# GD32H77x register map
File version: 1.0
CPU: CM7 r1p2, little endian, MPU, FPU, 4 interrupt priority bits
Registers are 32-bit, read-write, reset 0x0 unless marked. A register's access mark holds for its fields unless they carry their own. Offsets are from the block's base; [hi:lo] are bit positions.

## RDCM — Resolver-to-digital module
Base 0x40016400
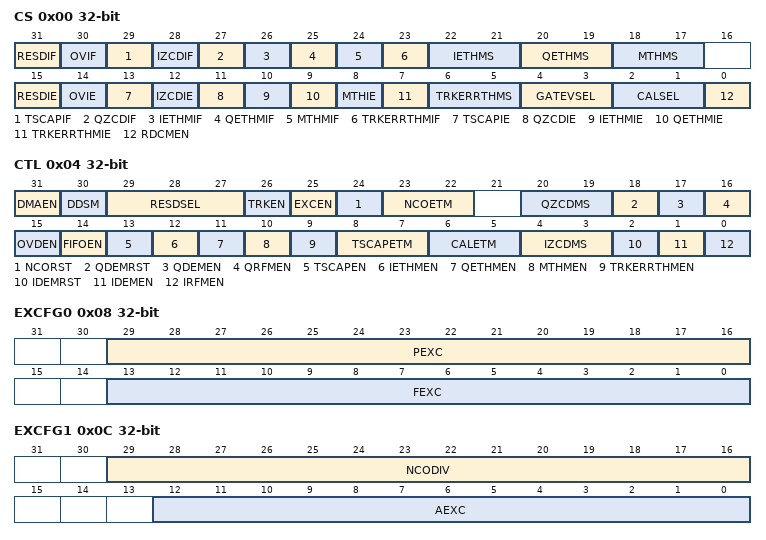
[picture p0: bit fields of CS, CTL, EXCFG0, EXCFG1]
0x00 CS — Control and status register
  [31] RESDIF — Result data interrupt flag.
  [30] OVIF — DMA transfer data register overflow interrupt flag
  [29] TSCAPIF — Timestamp counter capture interrupt flag.
  [28] IZCDIF — I channel zero crossing detection interrupt flag.
  [27] QZCDIF — Q channel zero crossing detection interrupt flag.
  [26] IETHMIF — I channel envelope signal threshold match interrupt flag.
  [25] QETHMIF — Q channel envelope signal threshold match interrupt flag.
  [24] MTHMIF — Monitor signal threshold match interrupt flag.
  [23] TRKERRTHMIF — Track error signal threshold match interrupt flag.
  [22:21] IETHMS — I channel envelope signal threshold mode selection
  [20:19] QETHMS — Q channel envelope signal threshold mode selection
  [18:17] MTHMS — Monitor signal mode selection
  [15] RESDIE — Interrupt enable for RESDIF
  [14] OVIE — Interrupt enable for OVIF
  [13] TSCAPIE — Interrupt enable for TSCAPIF
  [12] IZCDIE — Interrupt enable for IZCDIF
  [11] QZCDIE — Interrupt enable for QZCDIF
  [10] IETHMIE — Interrupt enable for IETHMIF
  [9] QETHMIE — Interrupt enable for QETHMIF
  [8] MTHIE — Interrupt enable for MTHMIF
  [7] TRKERRTHMIE — Interrupt enable for TRKERRTHMIF
  [6:5] TRKERRTHMS — Tracking error signal threshold mode selection.
  [4:3] GATEVSEL — Gate signal (timestamp trigger) valid selection
  [2:1] CALSEL — RDCM main chain calculation event selection.
  [0] RDCMEN — RDCM enable.
0x04 CTL access per field — Control register
  [31] DMAEN rw — DMA request enable
  [30] DDSM rw — DMA disable mode
  [29:27] RESDSEL rw — Result data register selection.
  [26] TRKEN rw — Track loop enable
  [25] EXCEN rw — Sinusoidal exciter enable
  [24] NCORST wo — Reset the phase of all NCOs (Exciter and I/Q reference frequency mixer) to the initial setting phase
  [23:22] NCOETM rw — External trigger mode for all NCOs (Excitor, I/Q Reference Frequency Mixer) calculation.
  [20:19] QZCDMS rw — Zero crossing detection mode selection in Q channel
  [18] QDEMRST wo — Q channel demodulator reset
  [17] QDEMEN rw — Q channel demodulator enable
  [16] QRFMEN rw — Q channel reference frequency mixer enable
  [15] OVDEN rw — DMA transfer overflow detection enable.
  [14] FIFOEN rw — Result data FIFO enable.
  [13] TSCAPEN rw — Timestamp counter capture enable.
  [12] IETHMEN rw — I channel envelope signal threshold match enable.
  [11] QETHMEN rw — Q channel envelope signal threshold match enable.
  [10] MTHMEN rw — Monitor signal threshold match enable.
  [9] TRKERRTHMEN rw — Track error signal threshold match enable.
  [8:7] TSCAPETM rw — External trigger mode for timestamp counter capture.
  [6:5] CALETM rw — External trigger mode for RDCM main chain calculation (high-pass filter, demodulator, tracking loop).
  [4:3] IZCDMS rw — Zero crossing detection mode selection in I channel
  [2] IDEMRST wo — I channel demodulator reset
  [1] IDEMEN rw — I channel demodulator enable
  [0] IRFMEN rw — I channel reference frequency mixer enable
0x08 EXCFG0 — Exciter configuration register 0
  [29:16] PEXC — Initial phase of the exciter
  [13:0] FEXC — Frequency of the exciter
0x0C EXCFG1 — Exciter configuration register 1
  [29:16] NCODIV — NCO(Excitror,I/Q reference frequency mixer) calculation frequency division factor
  [12:0] AEXC — Amplitude of the exciter
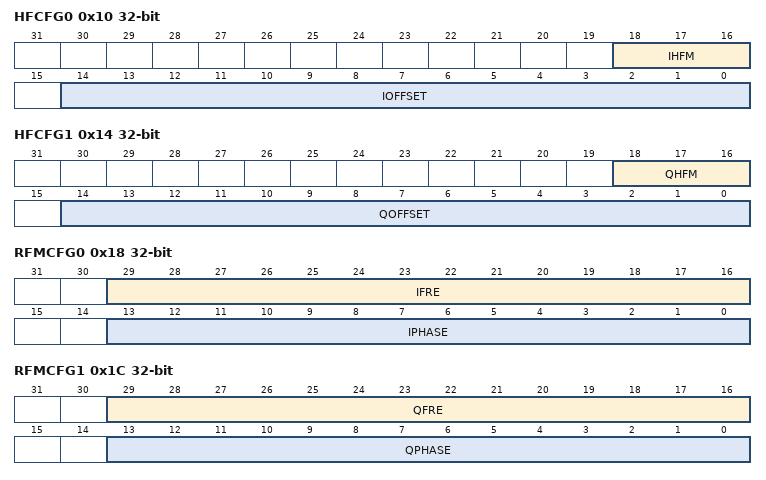
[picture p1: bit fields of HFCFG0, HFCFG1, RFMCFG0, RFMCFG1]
0x10 HFCFG0 — High pass filter configuration register 0
  [18:16] IHFM — I channel high-pass (offset compensation) filter mode
  [14:0] IOFFSET — I channel offset factor
0x14 HFCFG1 — High pass filter configuration register 1
  [18:16] QHFM — Q channel high-pass (offset compensation) filter mode
  [14:0] QOFFSET — Q channel offset factor
0x18 RFMCFG0 — Reference frequency mixer configuration register 0
  [29:16] IFRE — The frequency control word of the I channel reference frequency mixer.
  [13:0] IPHASE — Initial phase of the I channel reference frequency mixer.
0x1C RFMCFG1 — Reference frequency mixer configuration register 1
  [29:16] QFRE — The frequency control word of the Q channel reference frequency mixer.
  [13:0] QPHASE — Initial phase of the Q channel reference frequency mixer.
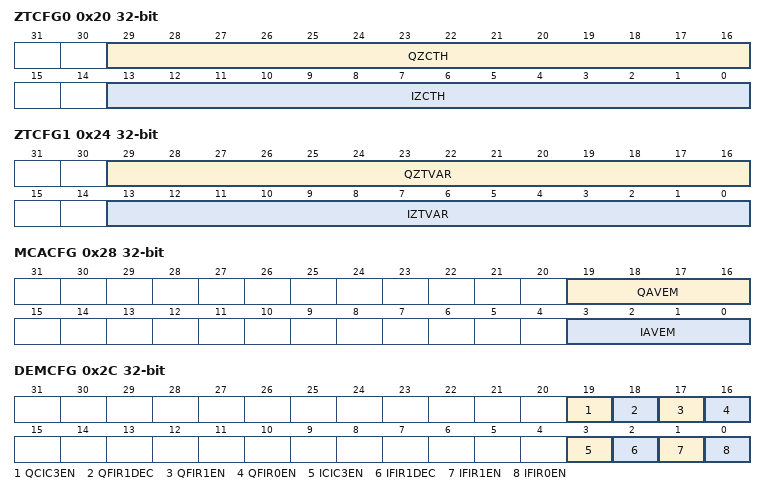
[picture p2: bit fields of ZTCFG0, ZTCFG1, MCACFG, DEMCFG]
0x20 ZTCFG0 — Zero crossing threshold configuration register 0
  [29:16] QZCTH — The threshold of mismatch counter value in zero crossing detection of Q channel.
  [13:0] IZCTH — The threshold of mismatch counter value in zero crossing detection of I channel.
0x24 ZTCFG1 — Zero crossing threshold configuration register 1
  [29:16] QZTVAR — The threshold variation range of mismatch counter value in zero crossing detection of Q channel.
  [13:0] IZTVAR — The threshold variation range of mismatch counter value in zero crossing detection of I channel.
0x28 MCACFG — Mismatch counter average configuration register
  [19:16] QAVEM — The mismatch counter average factor of Q channel.
  [3:0] IAVEM — The mismatch counter average factor of I channel.
0x2C DEMCFG — Demodulator configuration register
  [19] QCIC3EN — Q channel CIC3 filter enable
  [18] QFIR1DEC — Q channel FIR1 filter decimation rate
  [17] QFIR1EN — Q channel FIR1 filter enable
  [16] QFIR0EN — Q channel FIR0 filter enable
  [3] ICIC3EN — I channel CIC3 filter enable
  [2] IFIR1DEC — I channel FIR1 filter decimation rate
  [1] IFIR1EN — I channel FIR1 filter enable
  [0] IFIR0EN — I channel FIR0 filter enable
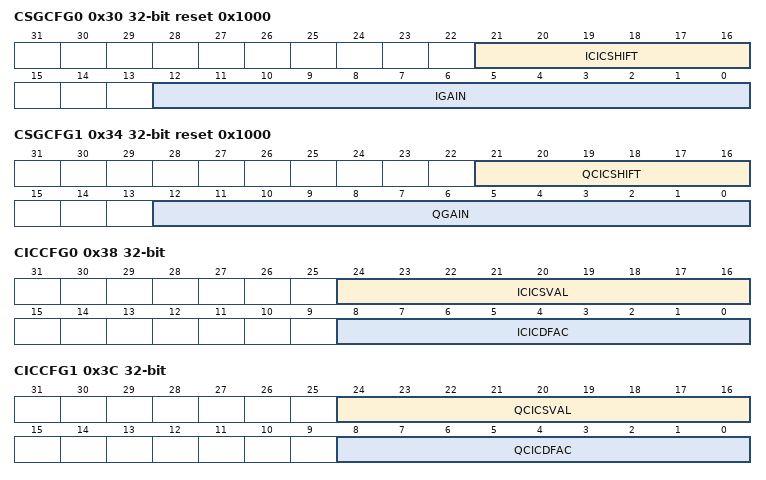
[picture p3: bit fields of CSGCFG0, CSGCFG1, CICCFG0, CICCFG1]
0x30 CSGCFG0 reset 0x1000 — CIC3 shift and gain configuration register 0
  [21:16] ICICSHIFT — I channel output shift
  [12:0] IGAIN — I channel gain factor
0x34 CSGCFG1 reset 0x1000 — CIC3 shift and gain configuration register 1
  [21:16] QCICSHIFT — Q channel output shift
  [12:0] QGAIN — Q channel gain factor
0x38 CICCFG0 — CIC3 configuration register 0
  [24:16] ICICSVAL — I channel CIC filter start value
  [8:0] ICICDFAC — I channel CIC filter decimation factor
0x3C CICCFG1 — CIC3 configuration register 1
  [24:16] QCICSVAL — Q channel CIC filter start value
  [8:0] QCICDFAC — Q channel CIC filter decimation factor
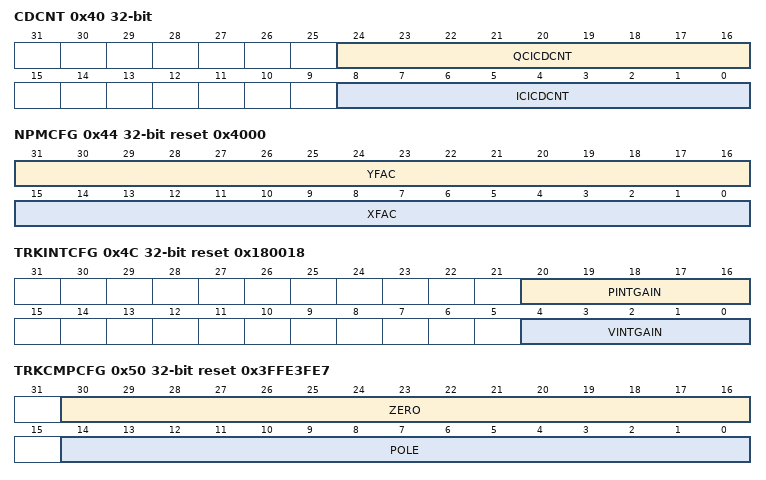
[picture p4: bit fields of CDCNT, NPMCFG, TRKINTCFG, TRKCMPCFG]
0x40 CDCNT ro — CIC3 decimation counter register
  [24:16] QCICDCNT — Q channel CIC3 filter decimation counter
  [8:0] ICICDCNT — I channel CIC3 Filter decimation counter
0x44 NPMCFG reset 0x4000 — Nonorthogonal phase mismatch configuration register
  [31:16] YFAC — Q channel nonorthogonal phase mismatch compensation factor Y.
  [15:0] XFAC — Q channel nonorthogonal phase mismatch compensation factor X.
0x48 TRKGAINCFG reset 0x1394FF16 — Tracking gain configuration register
  [28:0] TRKERRGAIN — The error acceleration gain factor.
0x4C TRKINTCFG reset 0x180018 — Tracking integrator configuration register
  [20:16] PINTGAIN — The position gain factor of integrator
  [4:0] VINTGAIN — The velocity gain factor of integrator
0x50 TRKCMPCFG reset 0x3FFE3FE7 — Tracking compensation configuration register
  [30:16] ZERO — The zero of compensation filter.
  [14:0] POLE — The pole of compensation filter.
0x54 VSFCFG — Velocity smooth filter configuration register
  [3:0] VSFM — The velocity smooth filter mode in tracking loop.
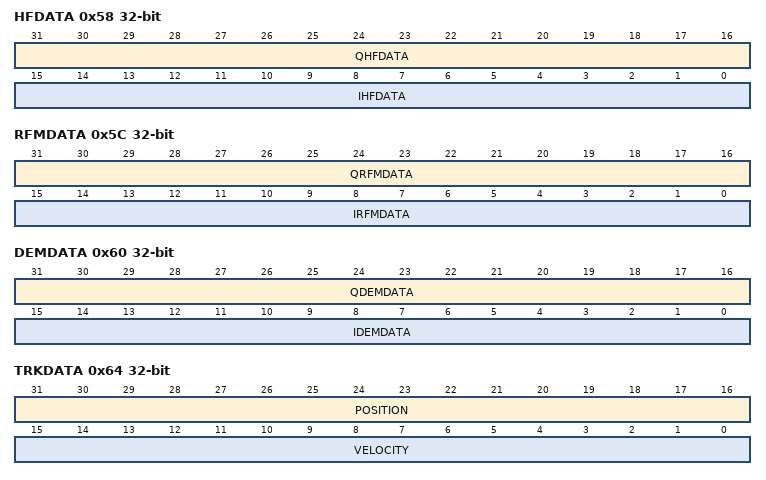
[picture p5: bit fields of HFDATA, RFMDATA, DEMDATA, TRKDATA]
0x58 HFDATA ro — High pass filter data register
  [31:16] QHFDATA — Data output from Q channel high pass filter.
  [15:0] IHFDATA — Data output from I channel high pass filter.
0x5C RFMDATA ro — Reference frequency mixer data register
  [31:16] QRFMDATA — Data output from Q channel reference frequency mixer.
  [15:0] IRFMDATA — Data output from I channel reference frequency mixer.
0x60 DEMDATA ro — Demodulator data register
  [31:16] QDEMDATA — Data output from Q channel phase sensitive demodulator.
  [15:0] IDEMDATA — Data output from I channel phase sensitive demodulator.
0x64 TRKDATA ro — Tracking data register
  [31:16] POSITION — Position data
  [15:0] VELOCITY — Velocity data
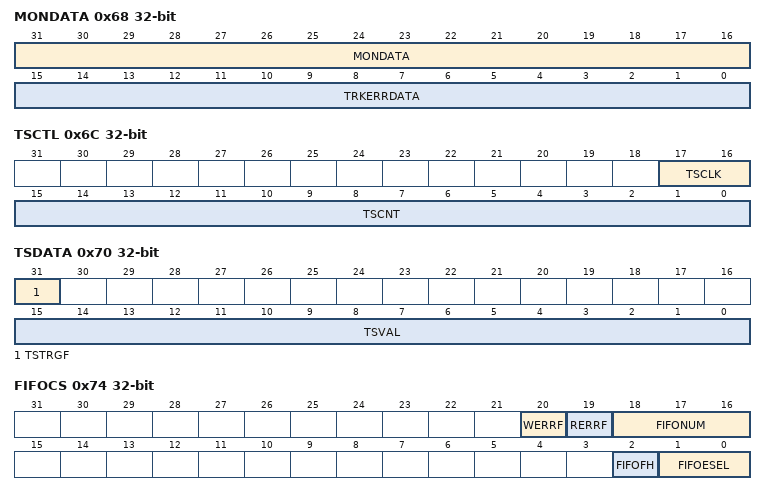
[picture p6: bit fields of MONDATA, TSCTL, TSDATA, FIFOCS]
0x68 MONDATA ro — Monitor data register
  [31:16] MONDATA — Monitor signal data
  [15:0] TRKERRDATA — Tracking error signal data
0x6C TSCTL access per field — Timestamp control register
  [17:16] TSCLK rw — Timestamp counter clock selection
  [15:0] TSCNT ro — Timestamp counter value
0x70 TSDATA access per field — Timestamp data register
  [31] TSTRGF rw — Timestamp trigger flag
  [15:0] TSVAL ro — The most recent captured timestamp value
0x74 FIFOCS access per field — FIFO control and status register
  [20] WERRF rw — Write error flag.
  [19] RERRF rw — Read error flag.
  [18:16] FIFONUM ro — FIFO valid data number
  [2] FIFOFH wo — FIFO flush
  [1:0] FIFOESEL rw — FIFO result event selection
0x78 FIFODATA ro
  [31:0] FIFODATA — FIFO data from result data register
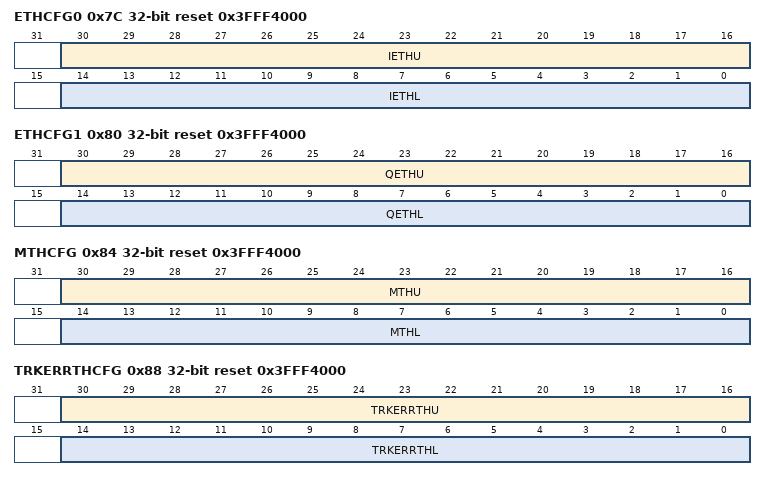
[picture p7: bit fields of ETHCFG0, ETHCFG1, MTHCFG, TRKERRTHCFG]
0x7C ETHCFG0 reset 0x3FFF4000 — Envelop threshold configuration register 0
  [30:16] IETHU — Upper threshold for envelope signal of I channel.
  [14:0] IETHL — Lower threshold for envelope signal of I channel.
0x80 ETHCFG1 reset 0x3FFF4000 — Envelop threshold configuration register 1
  [30:16] QETHU — Upper threshold for envelope signal of Q channel.
  [14:0] QETHL — Lower threshold for envelope signal of Q channel.
0x84 MTHCFG reset 0x3FFF4000 — Monitor signal threshold configuration register
  [30:16] MTHU — Upper threshold for monitor signal.
  [14:0] MTHL — Lower threshold for monitor signal.
0x88 TRKERRTHCFG reset 0x3FFF4000 — Tracking error signal threshold configuration register
  [30:16] TRKERRTHU — Upper threshold for tracking error signal.
  [14:0] TRKERRTHL — Lower threshold for tracking error signal.
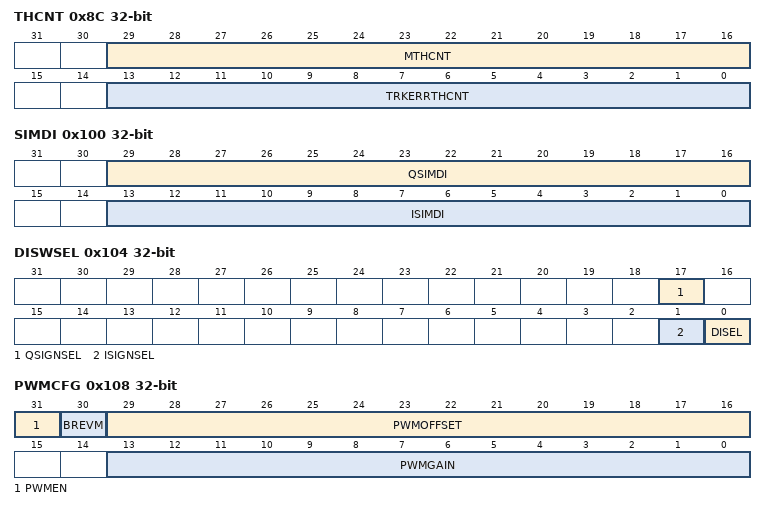
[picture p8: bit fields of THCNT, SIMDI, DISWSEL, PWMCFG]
0x8C THCNT — Threshold match counter register
  [29:16] MTHCNT — The monitor signal threshold match counter value.
  [13:0] TRKERRTHCNT — The tracking error signal threshold match counter value.
0x100 SIMDI — Simulation data input register
  [29:16] QSIMDI — Simulation Q channel Data input.
  [13:0] ISIMDI — Simulation I channel Data input.
0x104 DISWSEL — Data input software selection register
  [17] QSIGNSEL — Q channel RDCM frequency mixer reference sign source selection.
  [1] ISIGNSEL — I channel RDCM frequency mixer reference sign source selection.
  [0] DISEL — RDCM data input selection
0x108 PWMCFG — PWM configuration register
  [31] PWMEN — PWM waveform generator enable.
  [30] BREVM — Bit-reversed mode for PWM value.
  [29:16] PWMOFFSET — PWM offset for PWM value.
  [13:0] PWMGAIN — PWM gain for PWM value.
0x10C POSDATA ro — Position data register
  [15:0] POSITION — Position data.
0x110 VELDATA ro — Velocity data register
  [15:0] VELOCITY — Velocity data.
